AUTOSAR XML (schema 4-0-3)
standard types defined: Boolean, UInt16, UInt32, UInt8
package /AUTOSAR_Platform/DataConstrs
  range DC_Boolean: raw 0..1
  range DC_UInt16: raw 0..65535
  range DC_UInt8: raw 0..255
package /PATAC/MSM/ComponentTypes
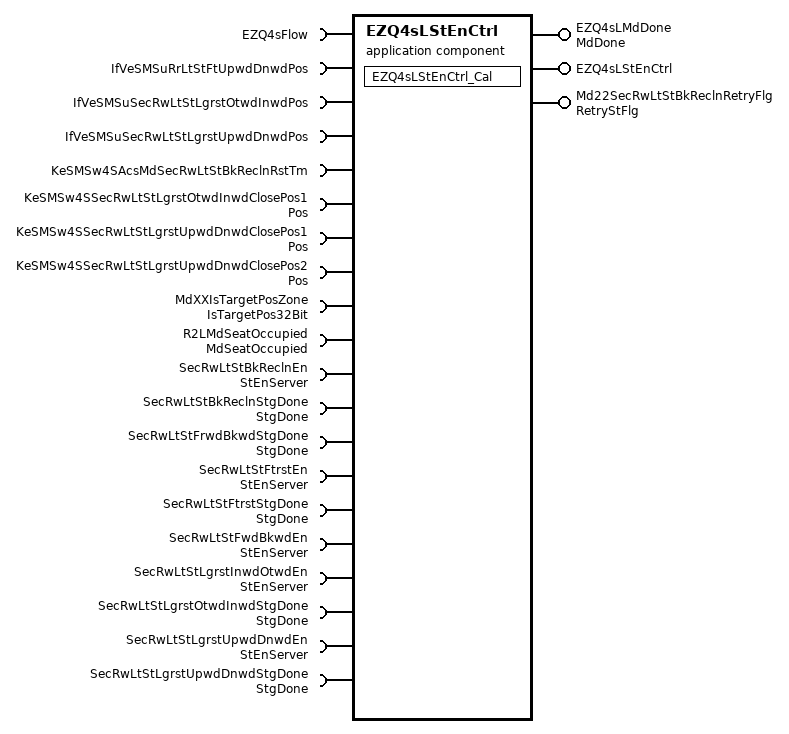
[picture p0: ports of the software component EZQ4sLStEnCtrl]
  application sw component type EZQ4sLStEnCtrl
    provide port EZQ4sLMdDone: nonqueued-sender-com-spec{data-element=MdDone/Val, init-value=0}, provided-interface=MdDone
    provide port EZQ4sLStEnCtrl: server-com-spec{operation=EZQ4sLStEnCtrl/Cal, queue-length=1}, provided-interface=EZQ4sLStEnCtrl
    provide port Md22SecRwLtStBkReclnRetryFlg: nonqueued-sender-com-spec=data-element=RetryStFlg/Val, provided-interface=RetryStFlg
    20 x require port:
      EZQ4sFlow: client-com-spec=EZQ4sFlow/Cal, required-interface=EZQ4sFlow
      IfVeSMSuRrLtStFtUpwdDnwdPos: nonqueued-receiver-com-spec{data-element=IfVeSMSuRrLtStFtUpwdDnwdPos/Val, filter=data-filter-type=ALWAYS, init-value=0}, required-interface=IfVeSMSuRrLtStFtUpwdDnwdPos
      IfVeSMSuSecRwLtStLgrstOtwdInwdPos: nonqueued-receiver-com-spec{data-element=IfVeSMSuSecRwLtStLgrstOtwdInwdPos/Val, filter=data-filter-type=ALWAYS, init-value=0}, required-interface=IfVeSMSuSecRwLtStLgrstOtwdInwdPos
      IfVeSMSuSecRwLtStLgrstUpwdDnwdPos: nonqueued-receiver-com-spec{data-element=IfVeSMSuSecRwLtStLgrstUpwdDnwdPos/Val, filter=data-filter-type=ALWAYS, init-value=0}, required-interface=IfVeSMSuSecRwLtStLgrstUpwdDnwdPos
      KeSMSw4SAcsMdSecRwLtStBkReclnRstTm: parameter-require-com-spec{init-value=1500, parameter=KeSMSw4SAcsMdSecRwLtStBkReclnRstTm/Val}, required-interface=KeSMSw4SAcsMdSecRwLtStBkReclnRstTm
      KeSMSw4SSecRwLtStLgrstOtwdInwdClosePos1: parameter-require-com-spec{init-value=0, parameter=Pos/Val}, required-interface=Pos
      KeSMSw4SSecRwLtStLgrstUpwdDnwdClosePos1: parameter-require-com-spec{init-value=0, parameter=Pos/Val}, required-interface=Pos
      KeSMSw4SSecRwLtStLgrstUpwdDnwdClosePos2: parameter-require-com-spec{init-value=0, parameter=Pos/Val}, required-interface=Pos
      MdXXIsTargetPosZone: nonqueued-receiver-com-spec{data-element=IsTargetPos32Bit/Val, filter=data-filter-type=ALWAYS, init-value=0}, required-interface=IsTargetPos32Bit
      R2LMdSeatOccupied: nonqueued-receiver-com-spec{data-element=MdSeatOccupied/Val, filter=data-filter-type=ALWAYS, init-value=0}, required-interface=MdSeatOccupied
      SecRwLtStBkReclnEn: required-com-specs=[Clear, Get, Set], required-interface=StEnServer
      SecRwLtStBkReclnStgDone: nonqueued-receiver-com-spec{data-element=StgDone/Val, filter=data-filter-type=ALWAYS, init-value=0}, required-interface=StgDone
      SecRwLtStFrwdBkwdStgDone: nonqueued-receiver-com-spec{data-element=StgDone/Val, filter=data-filter-type=ALWAYS, init-value=0}, required-interface=StgDone
      SecRwLtStFtrstEn: required-com-specs=[Clear, Get, Set], required-interface=StEnServer
      SecRwLtStFtrstStgDone: nonqueued-receiver-com-spec{data-element=StgDone/Val, filter=data-filter-type=ALWAYS, init-value=0}, required-interface=StgDone
      SecRwLtStFwdBkwdEn: required-com-specs=[Clear, Get, Set], required-interface=StEnServer
      SecRwLtStLgrstInwdOtwdEn: required-com-specs=[Clear, Get, Set], required-interface=StEnServer
      SecRwLtStLgrstOtwdInwdStgDone: nonqueued-receiver-com-spec{data-element=StgDone/Val, filter=data-filter-type=ALWAYS, init-value=0}, required-interface=StgDone
      SecRwLtStLgrstUpwdDnwdEn: required-com-specs=[Clear, Get, Set], required-interface=StEnServer
      SecRwLtStLgrstUpwdDnwdStgDone: nonqueued-receiver-com-spec{data-element=StgDone/Val, filter=data-filter-type=ALWAYS, init-value=0}, required-interface=StgDone
    behavior EZQ4sLStEnCtrl_InternalBehavior
      operation invoked event OIT_EZQ4sLStEnCtrl_Cal_EZQ4sLStEnCtrl_Cal: start-on-event=EZQ4sLStEnCtrl_Cal, operation=EZQ4sLStEnCtrl.Cal
      runnable EZQ4sLStEnCtrl_Cal
        data-receive-point-by-arguments:
          10 x access:
            REC_IfVeSMSuRrLtStFtUpwdDnwdPos_Val: accessed-variable=IfVeSMSuRrLtStFtUpwdDnwdPos.Val
            REC_IfVeSMSuSecRwLtStLgrstOtwdInwdPos_Val: accessed-variable=IfVeSMSuSecRwLtStLgrstOtwdInwdPos.Val
            REC_IfVeSMSuSecRwLtStLgrstUpwdDnwdPos_Val: accessed-variable=IfVeSMSuSecRwLtStLgrstUpwdDnwdPos.Val
            REC_MdXXIsTargetPosZone_Val: accessed-variable=MdXXIsTargetPosZone.Val
            REC_R2LMdSeatOccupied_Val: accessed-variable=R2LMdSeatOccupied.Val
            REC_SecRwLtStBkReclnStgDone_Val: accessed-variable=SecRwLtStBkReclnStgDone.Val
            REC_SecRwLtStFrwdBkwdStgDone_Val: accessed-variable=SecRwLtStFrwdBkwdStgDone.Val
            REC_SecRwLtStFtrstStgDone_Val: accessed-variable=SecRwLtStFtrstStgDone.Val
            REC_SecRwLtStLgrstOtwdInwdStgDone_Val: accessed-variable=SecRwLtStLgrstOtwdInwdStgDone.Val
            REC_SecRwLtStLgrstUpwdDnwdStgDone_Val: accessed-variable=SecRwLtStLgrstUpwdDnwdStgDone.Val
        data-send-points:
          access SEND_EZQ4sLMdDone_Val: accessed-variable=EZQ4sLMdDone.Val
          access SEND_Md22SecRwLtStBkReclnRetryFlg_Val: accessed-variable=Md22SecRwLtStBkReclnRetryFlg.Val
        4 x parameter access:
          PA_KeSMSw4SAcsMdSecRwLtStBkReclnRstTm_Val: accessed-parameter=KeSMSw4SAcsMdSecRwLtStBkReclnRstTm.Val
          PA_KeSMSw4SSecRwLtStLgrstOtwdInwdClosePos1_Val: accessed-parameter=KeSMSw4SSecRwLtStLgrstOtwdInwdClosePos1.Val
          PA_KeSMSw4SSecRwLtStLgrstUpwdDnwdClosePos1_Val: accessed-parameter=KeSMSw4SSecRwLtStLgrstUpwdDnwdClosePos1.Val
          PA_KeSMSw4SSecRwLtStLgrstUpwdDnwdClosePos2_Val: accessed-parameter=KeSMSw4SSecRwLtStLgrstUpwdDnwdClosePos2.Val
        11 x sync call, all with timeout=0:
          SC_EZQ4sFlow_Cal: operation=EZQ4sFlow.Cal
          SC_SecRwLtStBkReclnEn_Clear: operation=SecRwLtStBkReclnEn.Clear
          SC_SecRwLtStBkReclnEn_Set: operation=SecRwLtStBkReclnEn.Set
          SC_SecRwLtStFtrstEn_Clear: operation=SecRwLtStFtrstEn.Clear
          SC_SecRwLtStFtrstEn_Set: operation=SecRwLtStFtrstEn.Set
          SC_SecRwLtStFwdBkwdEn_Clear: operation=SecRwLtStFwdBkwdEn.Clear
          SC_SecRwLtStFwdBkwdEn_Set: operation=SecRwLtStFwdBkwdEn.Set
          SC_SecRwLtStLgrstInwdOtwdEn_Clear: operation=SecRwLtStLgrstInwdOtwdEn.Clear
          SC_SecRwLtStLgrstInwdOtwdEn_Set: operation=SecRwLtStLgrstInwdOtwdEn.Set
          SC_SecRwLtStLgrstUpwdDnwdEn_Clear: operation=SecRwLtStLgrstUpwdDnwdEn.Clear
          SC_SecRwLtStLgrstUpwdDnwdEn_Set: operation=SecRwLtStLgrstUpwdDnwdEn.Set
  swc implementation EZQ4sLStEnCtrl_Implementation: behavior=EZQ4sLStEnCtrl_InternalBehavior
    code-descriptors:
      code Default: artifact-descriptors=autosar-engineering-object={short-label=Default, category=SWSRC}
package /PATAC/MSM/ModeAdjust/CalPortInterface
  parameter interface KeSMSw4SAcsMdSecRwLtStBkReclnRstTm
    parameter data prototype Val: sw-calibration-access=READ-WRITE, type=UInt16
  parameter interface Pos
    parameter data prototype Val: sw-calibration-access=READ-WRITE, type=UInt16
package /PATAC/MSM/ModeAdjust/PortInterface
  client server interface EZQ4sFlow
    operation Cal
      20 x arg, all with server-argument-impl-policy=USE-ARGUMENT-TYPE:
        LgrstUpwdDnwdPos: type=UInt16, direction=IN
        LgrstOtwdInwdPos: type=UInt16, direction=IN
        FtUpwdDnwdPos: type=UInt16, direction=IN
        CloseDnwdPos1: type=UInt16, direction=IN
        CloseDnwdPos2: type=UInt16, direction=IN
        CloseOtwdPos1: type=UInt16, direction=IN
        LgrstInwdStgDone: type=Implementation/Boolean, direction=IN
        LgrstUpwdStgDone: type=Implementation/Boolean, direction=IN
        FtrstStgDone: type=Implementation/Boolean, direction=IN
        FrwdBkwdStgDone: type=DataTypes/Boolean, direction=IN
        BkReclnStgDone: type=DataTypes/Boolean, direction=IN
        StEmpty: type=DataTypes/Boolean, direction=IN
        Failflg: type=Implementation/Boolean, direction=OUT
        LgrstInwdOtwdEn: type=Implementation/Boolean, direction=OUT
        LgrstUpwdDnwdEn: type=Implementation/Boolean, direction=OUT
        FtrstEn: type=Implementation/Boolean, direction=OUT
        FrwdBkwdEn: type=DataTypes/Boolean, direction=OUT
        BkReclnEn: type=DataTypes/Boolean, direction=OUT
        WaitComplete: type=DataTypes/Boolean, direction=IN
        RetryStFlg: type=DataTypes/Boolean, direction=OUT
  client server interface EZQ4sLStEnCtrl
    operation Cal
      arg ResetCond: type=DataTypes/Boolean, direction=IN, server-argument-impl-policy=USE-ARGUMENT-TYPE
  client server interface StEnServer
    operation Clear
      arg data: type=UInt8, direction=IN, server-argument-impl-policy=USE-ARGUMENT-TYPE
    operation Get
      arg data: type=UInt32, direction=OUT, server-argument-impl-policy=USE-ARGUMENT-TYPE
    operation Set
      arg data: type=UInt8, direction=IN, server-argument-impl-policy=USE-ARGUMENT-TYPE
  5 x sender receiver interface:
    IsTargetPos32Bit: invalidation-policy{data-element=IsTargetPos32Bit/Val, handle-invalid=DONT-INVALIDATE}
      data Val: type=UInt32
    MdDone: invalidation-policy{data-element=MdDone/Val, handle-invalid=DONT-INVALIDATE}
      data Val: type=UInt8
    MdSeatOccupied: invalidation-policy{data-element=MdSeatOccupied/Val, handle-invalid=DONT-INVALIDATE}
      data Val: type=Implementation/Boolean
    RetryStFlg: invalidation-policy{data-element=RetryStFlg/Val, handle-invalid=DONT-INVALIDATE}
      data Val: type=Implementation/Boolean
    StgDone: invalidation-policy{data-element=StgDone/Val, handle-invalid=DONT-INVALIDATE}
      data Val: type=Implementation/Boolean
package /PATAC/MSM/PortInterfaces
  sender receiver interface IfVeSMSuRrLtStFtUpwdDnwdPos: invalidation-policy{data-element=IfVeSMSuRrLtStFtUpwdDnwdPos/Val, handle-invalid=DONT-INVALIDATE}
    data Val: type=UInt16
  sender receiver interface IfVeSMSuSecRwLtStLgrstOtwdInwdPos: invalidation-policy{data-element=IfVeSMSuSecRwLtStLgrstOtwdInwdPos/Val, handle-invalid=DONT-INVALIDATE}
    data Val: type=UInt16
  sender receiver interface IfVeSMSuSecRwLtStLgrstUpwdDnwdPos: invalidation-policy{data-element=IfVeSMSuSecRwLtStLgrstUpwdDnwdPos/Val, handle-invalid=DONT-INVALIDATE}
    data Val: type=UInt16
